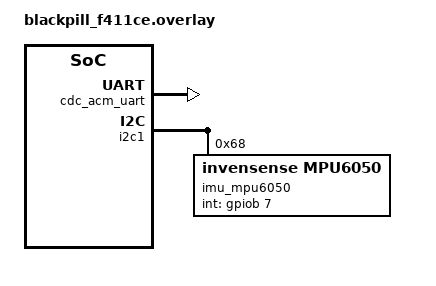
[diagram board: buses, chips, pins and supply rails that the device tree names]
/*
 * This file is part of the efc project <https://github.com/eurus-project/efc/>.
 * Copyright (c) 2024 The efc developers.
 *
 * This program is free software: you can redistribute it and/or modify
 * it under the terms of the GNU General Public License as published by
 * the Free Software Foundation, version 3.
 *
 * This program is distributed in the hope that it will be useful, but
 * WITHOUT ANY WARRANTY; without even the implied warranty of
 * MERCHANTABILITY or FITNESS FOR A PARTICULAR PURPOSE. See the GNU
 * General Public License for more details.
 *
 * You should have received a copy of the GNU General Public License
 * along with this program. If not, see <http://www.gnu.org/licenses/>.
 */

#include <zephyr/dt-bindings/sensor/icm42688.h>

/ {
	chosen {
		zephyr,console = &cdc_acm_uart;
		zephyr,shell-uart = &cdc_acm_uart;
	};
};

&zephyr_udc0 {
	cdc_acm_uart: cdc_acm_uart0 {
		compatible = "zephyr,cdc-acm-uart";
	};
};

&i2c1 {
	imu_mpu6050: mpu6050@68 {
		compatible = "invensense,mpu6050";
		reg = <0x68>;
		status = "okay";
		int-gpios = <&gpiob 7 GPIO_ACTIVE_HIGH>;
	};
};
